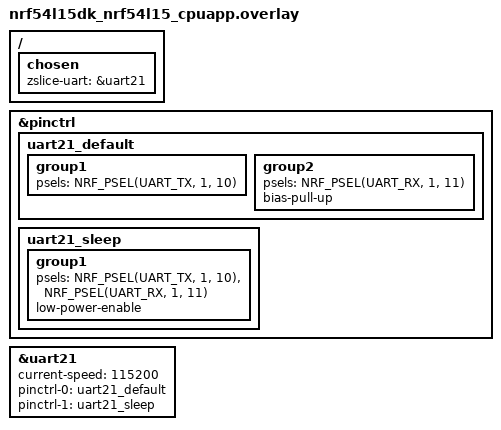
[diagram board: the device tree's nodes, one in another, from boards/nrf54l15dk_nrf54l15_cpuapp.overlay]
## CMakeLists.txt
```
# SPDX-License-Identifier: Apache-2.0

cmake_minimum_required(VERSION 3.20.0)

find_package(Zephyr REQUIRED HINTS $ENV{ZEPHYR_BASE})
project(nanopb_sample)

list(APPEND CMAKE_MODULE_PATH ${ZEPHYR_BASE}/modules/nanopb)
include(nanopb)

zephyr_nanopb_sources(app src/request.proto
						  src/response.proto
)

FILE(GLOB app_sources src/*.c)
target_sources(app PRIVATE ${app_sources})
```

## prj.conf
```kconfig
CONFIG_LOG=y
CONFIG_SERIAL=y
CONFIG_ZSLICE=y
```

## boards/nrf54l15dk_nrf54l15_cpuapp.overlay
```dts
/ {
	chosen {
		zslice-uart = &uart21;
	};
};

&pinctrl {
	/omit-if-no-ref/ uart21_default: uart21_default {
		group1 {
			psels = <NRF_PSEL(UART_TX, 1, 10)>;
		};

		group2 {
			psels = <NRF_PSEL(UART_RX, 1, 11)>;
			bias-pull-up;
		};
	};

	/omit-if-no-ref/ uart21_sleep: uart21_sleep {
		group1 {
			psels = <NRF_PSEL(UART_TX, 1, 10)>,
				<NRF_PSEL(UART_RX, 1, 11)>;
			low-power-enable;
		};
	};
};

&uart21 {
	status = "okay";
	current-speed = <115200>;
	pinctrl-0 = <&uart21_default>;
	pinctrl-1 = <&uart21_sleep>;
	pinctrl-names = "default", "sleep";
};
```

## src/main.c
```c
/*
 * Copyright (c) 2011 Petteri Aimonen
 * Copyright (c) 2021 Basalte bv
 *
 * SPDX-License-Identifier: Apache-2.0
 */

#include <zephyr/kernel.h>
#include <zephyr/sys/printk.h>

#include <pb_encode.h>
#include <pb_decode.h>
#include "src/request.pb.h"
#include "src/response.pb.h"

#include <zslice.h>

static void handle_add(const Request *req, Response *resp, void *user_data)
{
    (void)user_data;
}

static void handle_subtract(const Request *req, Response *resp, void *user_data)
{
    (void)user_data;
}

/*
 * =========================================================================
 * zslice Service Table
 * =========================================================================
 */
ZSLICE_SERVICE_DEFINE(math_service, DT_CHOSEN(zslice_uart), 128, sizeof(Request_msg), NULL,
    ZSLICE_HANDLER(
        RequestTypes_ADD,
        &Request_msg,
        &Response_msg,
        handle_add,
        ZSLICE_FLAG_NONE
    ),
    ZSLICE_HANDLER(
        RequestTypes_SUBTRACT,
        &Request_msg,
        &Response_msg,
        handle_subtract,
        ZSLICE_FLAG_NONE
    ),
);
```
